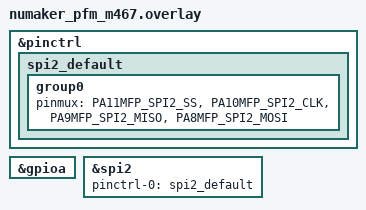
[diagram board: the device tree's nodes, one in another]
/* SPDX-FileCopyrightText: Copyright The Zephyr Project Contributors */
/* SPDX-License-Identifier: Apache-2.0 */

&pinctrl {
	/* EVB's NU5: SS/CLK/MISO/MOSI */
	spi2_default: spi2_default {
		group0 {
			pinmux = <PA11MFP_SPI2_SS>,
				 <PA10MFP_SPI2_CLK>,
				 <PA9MFP_SPI2_MISO>,
				 <PA8MFP_SPI2_MOSI>;
		};
	};
};

&gpioa {
	status = "okay";
};

spi_loopback: &spi2 {
	status = "okay";
	pinctrl-0 = <&spi2_default>;
	pinctrl-names = "default";
};

#include "../spi-loopback.dtsi"
